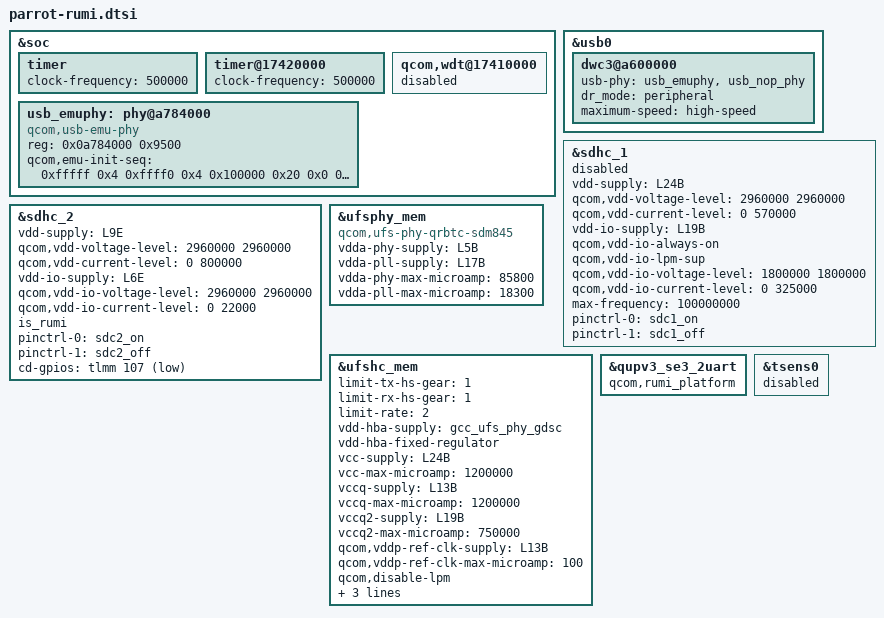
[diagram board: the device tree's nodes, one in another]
#include <dt-bindings/clock/qcom,gcc-parrot.h>
#include <dt-bindings/gpio/gpio.h>

&soc {
	timer {
		clock-frequency = <500000>;
	};

	timer@17420000 {
		clock-frequency = <500000>;
	};

	qcom,wdt@17410000 {
		status = "disabled";
	};

	usb_emuphy: phy@a784000 {
		compatible = "qcom,usb-emu-phy";
		reg = <0x0a784000 0x9500>;

		qcom,emu-init-seq = <0xfffff 0x4
		     0xffff0 0x4
		     0x100000 0x20
		     0x0 0x20
		     0x000001A0 0x20
		     0x00100000 0x3c
		     0x0 0x3c
		     0x0 0x4>;
	};
};

&usb0 {
	dwc3@a600000 {
		usb-phy = <&usb_emuphy>, <&usb_nop_phy>;
		dr_mode = "peripheral";
		maximum-speed = "high-speed";
	};
};

&sdhc_1 {
	status = "disabled";

	vdd-supply = <&L24B>;
	qcom,vdd-voltage-level = <2960000 2960000>;
	qcom,vdd-current-level = <0 570000>;

	vdd-io-supply = <&L19B>;
	qcom,vdd-io-always-on;
	qcom,vdd-io-lpm-sup;
	qcom,vdd-io-voltage-level = <1800000 1800000>;
	qcom,vdd-io-current-level = <0 325000>;

	/delete-property/ mmc-ddr-1_8v;
	/delete-property/ mmc-hs200-1_8v;
	/delete-property/ mmc-hs400-1_8v;
	/delete-property/ mmc-hs400-enhanced-strobe;
	max-frequency = <100000000>;

	pinctrl-names = "default", "sleep";
	pinctrl-0 = <&sdc1_on>;
	pinctrl-1 = <&sdc1_off>;
};

&sdhc_2 {
	status = "ok";
	vdd-supply = <&L9E>;
	qcom,vdd-voltage-level = <2960000 2960000>;
	qcom,vdd-current-level = <0 800000>;

	vdd-io-supply = <&L6E>;
	qcom,vdd-io-voltage-level = <2960000 2960000>;
	qcom,vdd-io-current-level = <0 22000>;

	is_rumi;

	pinctrl-names = "default", "sleep";
	pinctrl-0 = <&sdc2_on>;
	pinctrl-1 = <&sdc2_off>;

	cd-gpios = <&tlmm 107 GPIO_ACTIVE_LOW>;
};

&ufsphy_mem {
	compatible = "qcom,ufs-phy-qrbtc-sdm845";

	vdda-phy-supply = <&L5B>;
	vdda-pll-supply = <&L17B>;
	vdda-phy-max-microamp = <85800>;
	vdda-pll-max-microamp = <18300>;

	status = "ok";
};

&ufshc_mem {
	limit-tx-hs-gear = <1>;
	limit-rx-hs-gear = <1>;
	limit-rate = <2>; /* HS Rate-B */

	vdd-hba-supply = <&gcc_ufs_phy_gdsc>;
	vdd-hba-fixed-regulator;

	vcc-supply = <&L24B>;
	vcc-max-microamp = <1200000>;

	vccq-supply = <&L13B>;
	vccq-max-microamp = <1200000>;

	vccq2-supply = <&L19B>;
	vccq2-max-microamp = <750000>;

	qcom,vddp-ref-clk-supply = <&L13B>;
	qcom,vddp-ref-clk-max-microamp = <100>;

	qcom,disable-lpm;
	rpm-level = <0>;
	spm-level = <0>;

	qcom,iommu-dma = "bypass";

	status = "ok";
};

&qupv3_se3_2uart {
	qcom,rumi_platform;
};

&tsens0 {
	status = "disabled";
};
